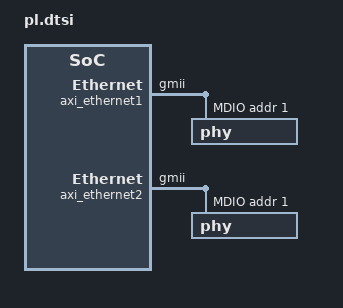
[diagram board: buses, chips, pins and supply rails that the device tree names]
/*
 * CAUTION: This file is automatically generated by Xilinx.
 * Version:  
 * Today is: Wed Jan 16 01:01:24 2019
 */


/ {
	amba_pl: amba_pl {
		#address-cells = <1>;
		#size-cells = <1>;
		compatible = "simple-bus";
		ranges ;
		axi_dma1: dma@40400000 {
			#dma-cells = <1>;
			axistream-connected = <&axi_ethernet1>;
			axistream-control-connected = <&axi_ethernet1>;
			clock-names = "s_axi_lite_aclk";
			clocks = <&clkc 16>;
			compatible = "xlnx,eth-dma";
			interrupt-names = "mm2s_introut", "s2mm_introut";
			interrupt-parent = <&intc>;
			interrupts = <0 30 4 0 29 4>;
			reg = <0x40400000 0x10000>;
			xlnx,include-dre ;
		};
		axi_dma2: dma@40410000 {
			#dma-cells = <1>;
			axistream-connected = <&axi_ethernet2>;
			axistream-control-connected = <&axi_ethernet2>;
			clock-names = "s_axi_lite_aclk";
			clocks = <&clkc 16>;
			compatible = "xlnx,eth-dma";
			interrupt-names = "mm2s_introut", "s2mm_introut";
			interrupt-parent = <&intc>;
			interrupts = <0 33 4 0 32 4>;
			reg = <0x40410000 0x10000>;
			xlnx,include-dre ;
		};
		axi_ethernet1: ethernet@41000000 {
			axistream-connected = <&axi_dma1>;
			axistream-control-connected = <&axi_dma1>;
			clock-frequency = <100000000>;
			clock-names = "ref_clk";
			clocks = <&clkc 0>;
			compatible = "xlnx,axi-ethernet-1.00.a";
			device_type = "network";
			interrupt-names = "interrupt";
			interrupt-parent = <&intc>;
			interrupts = <0 31 4>;
			phy-mode = "gmii";
			reg = <0x41000000 0x40000>;
			xlnx = <0x0>;
			xlnx,axiliteclkrate = <0x0>;
			xlnx,axisclkrate = <0x0>;
			xlnx,clockselection = <0x0>;
			xlnx,enableasyncsgmii = <0x0>;
			xlnx,gt-type = <0x0>;
			xlnx,gtinex = <0x0>;
			xlnx,gtlocation = <0x0>;
			xlnx,gtrefclksrc = <0x0>;
			xlnx,include-dre ;
			xlnx,instantiatebitslice0 = <0x0>;
			xlnx,phy-type = <0x1>;
			xlnx,phyaddr = <0x1>;
			xlnx,rable = <0x0>;
			xlnx,rxcsum = <0x2>;
			xlnx,rxlane0-placement = <0x0>;
			xlnx,rxlane1-placement = <0x0>;
			xlnx,rxmem = <0x4000>;
			xlnx,rxnibblebitslice0used = <0x0>;
			xlnx,tx-in-upper-nibble = <0x1>;
			xlnx,txcsum = <0x2>;
			xlnx,txlane0-placement = <0x0>;
			xlnx,txlane1-placement = <0x0>;
			phy-handle = <0x99>;
			local-mac-address = [de ad be ef 00 01];
			axi_ethernet1_mdio: mdio {
				#address-cells = <1>;
				#size-cells = <0>;
				phy@1 {
					device_type = "ethernet-phy";
					reg = <0x1>;
					linux,phandle = <0x99>;
					phandle = <0x99>;
				};
			};
		};
		axi_ethernet2: ethernet@41040000 {
			axistream-connected = <&axi_dma2>;
			axistream-control-connected = <&axi_dma2>;
			clock-frequency = <100000000>;
			clock-names = "ref_clk";
			clocks = <&clkc 0>;
			compatible = "xlnx,axi-ethernet-1.00.a";
			device_type = "network";
			interrupt-names = "interrupt";
			interrupt-parent = <&intc>;
			interrupts = <0 34 4>;
			phy-mode = "gmii";
			reg = <0x41040000 0x40000>;
			xlnx = <0x0>;
			xlnx,axiliteclkrate = <0x0>;
			xlnx,axisclkrate = <0x0>;
			xlnx,clockselection = <0x0>;
			xlnx,enableasyncsgmii = <0x0>;
			xlnx,gt-type = <0x0>;
			xlnx,gtinex = <0x0>;
			xlnx,gtlocation = <0x0>;
			xlnx,gtrefclksrc = <0x0>;
			xlnx,include-dre ;
			xlnx,instantiatebitslice0 = <0x0>;
			xlnx,phy-type = <0x1>;
			xlnx,phyaddr = <0x1>;
			xlnx,rable = <0x0>;
			xlnx,rxcsum = <0x2>;
			xlnx,rxlane0-placement = <0x0>;
			xlnx,rxlane1-placement = <0x0>;
			xlnx,rxmem = <0x4000>;
			xlnx,rxnibblebitslice0used = <0x0>;
			xlnx,tx-in-upper-nibble = <0x1>;
			xlnx,txcsum = <0x2>;
			xlnx,txlane0-placement = <0x0>;
			xlnx,txlane1-placement = <0x0>;
			phy-handle = <0x98>;
			local-mac-address = [de ad be ef 00 02];
			axi_ethernet2_mdio: mdio {
				#address-cells = <1>;
				#size-cells = <0>;
				phy@1 {
					device_type = "ethernet-phy";
					reg = <0x1>;
					linux,phandle = <0x98>;
					phandle = <0x98>;
				};
			};
		};
	};
};
